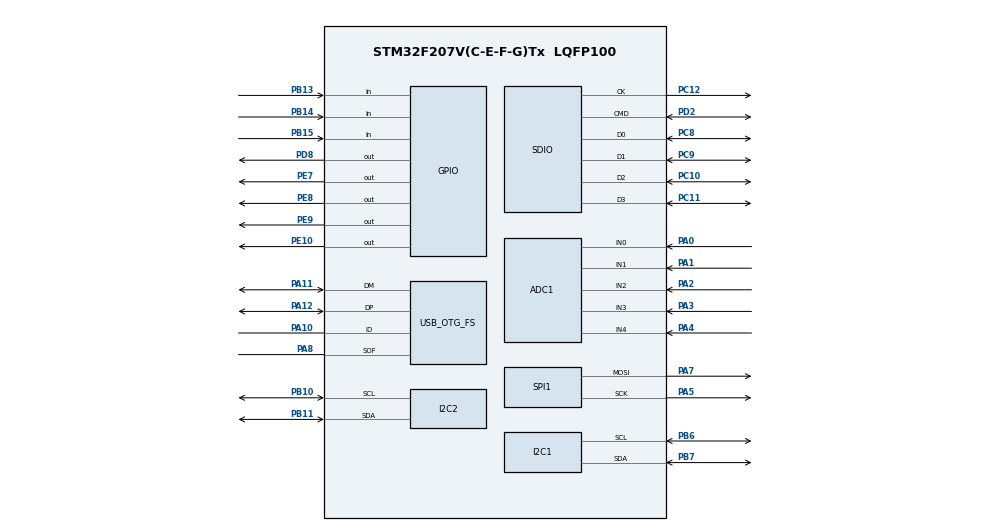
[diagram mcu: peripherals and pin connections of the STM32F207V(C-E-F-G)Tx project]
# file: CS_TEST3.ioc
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ADC1.Channel-0\#ChannelRegularConversion=ADC_CHANNEL_TEMPSENSOR
ADC1.NbrOfConversionFlag=1
ADC1.Rank-0\#ChannelRegularConversion=1
ADC1.SamplingTime-0\#ChannelRegularConversion=ADC_SAMPLETIME_3CYCLES
ADC1.master=1
Dma.I2C1_RX.1.Channel=DMA_CHANNEL_1
Dma.I2C1_RX.1.Direction=DMA_PERIPH_TO_MEMORY
Dma.I2C1_RX.1.FIFOMode=DMA_FIFOMODE_ENABLE
Dma.I2C1_RX.1.FIFOThreshold=DMA_FIFO_THRESHOLD_HALFFULL
Dma.I2C1_RX.1.Instance=DMA1_Stream0
Dma.I2C1_RX.1.MemBurst=DMA_MBURST_SINGLE
Dma.I2C1_RX.1.MemDataAlignment=DMA_MDATAALIGN_BYTE
Dma.I2C1_RX.1.MemInc=DMA_MINC_ENABLE
Dma.I2C1_RX.1.Mode=DMA_CIRCULAR
Dma.I2C1_RX.1.PeriphBurst=DMA_PBURST_SINGLE
Dma.I2C1_RX.1.PeriphDataAlignment=DMA_PDATAALIGN_BYTE
Dma.I2C1_RX.1.PeriphInc=DMA_PINC_DISABLE
Dma.I2C1_RX.1.Priority=DMA_PRIORITY_LOW
Dma.Request0=SDIO
Dma.Request1=I2C1_RX
Dma.SDIO.0.Channel=DMA_CHANNEL_4
Dma.SDIO.0.Direction=DMA_MEMORY_TO_PERIPH
Dma.SDIO.0.FIFOMode=DMA_FIFOMODE_ENABLE
Dma.SDIO.0.FIFOThreshold=DMA_FIFO_THRESHOLD_HALFFULL
Dma.SDIO.0.Instance=DMA2_Stream3
Dma.SDIO.0.MemBurst=DMA_MBURST_SINGLE
Dma.SDIO.0.MemDataAlignment=DMA_MDATAALIGN_BYTE
Dma.SDIO.0.MemInc=DMA_MINC_DISABLE
Dma.SDIO.0.Mode=DMA_PFCTRL
Dma.SDIO.0.PeriphBurst=DMA_PBURST_SINGLE
Dma.SDIO.0.PeriphDataAlignment=DMA_PDATAALIGN_BYTE
Dma.SDIO.0.PeriphInc=DMA_PINC_DISABLE
Dma.SDIO.0.Priority=DMA_PRIORITY_LOW
I2C1.GeneralCallMode=I2C_GENERALCALL_ENABLED
Mcu.Family=STM32F2
Mcu.Name=STM32F207V(C-E-F-G)Tx
Mcu.Package=LQFP100
NVIC.PriorityGroup=NVIC_PRIORITYGROUP_0
PA0-WKUP.Signal=ADCx_IN0
PA1.Signal=ADCx_IN1
PA10.Mode=OTG/Dual_Role_Device
PA10.Signal=USB_OTG_FS_ID
PA11.Mode=OTG/Dual_Role_Device
PA11.Signal=USB_OTG_FS_DM
PA12.Mode=OTG/Dual_Role_Device
PA12.Signal=USB_OTG_FS_DP
PA13.Mode=JTAG(4-pin)
PA13.Signal=SYS_JTMS-SWDIO
PA14.Mode=JTAG(4-pin)
PA14.Signal=SYS_JTCK-SWCLK
PA15.Mode=JTAG(4-pin)
PA15.Signal=SYS_JTDI
PA2.Signal=ADCx_IN2
PA3.Signal=ADCx_IN3
PA4.Signal=ADCx_IN4
PA5.Mode=TX_Only_Simplex_Unidirect_Master
PA5.Signal=SPI1_SCK
PA7.Mode=TX_Only_Simplex_Unidirect_Master
PA7.Signal=SPI1_MOSI
PA8.Mode=Activate_SOF_FS
PA8.Signal=USB_OTG_FS_SOF
PB10.Mode=I2C
PB10.Signal=I2C2_SCL
PB11.Mode=I2C
PB11.Signal=I2C2_SDA
PB13.GPIO_Mode=GPIO_MODE_INPUT
PB13.GPIO_PuPd=GPIO_PULLUP
PB13.Signal=GPIO_Input
PB14.GPIO_Mode=GPIO_MODE_INPUT
PB14.GPIO_PuPd=GPIO_PULLUP
PB14.Signal=GPIO_Input
PB15.GPIO_Mode=GPIO_MODE_INPUT
PB15.GPIO_PuPd=GPIO_PULLUP
PB15.Signal=GPIO_Input
PB3.Mode=JTAG(4-pin)
PB3.Signal=SYS_JTDO-SWO
PB6.Mode=I2C
PB6.Signal=I2C1_SCL
PB7.Mode=I2C
PB7.Signal=I2C1_SDA
PC10.Mode=SD_4_bits_Wide_bus
PC10.Signal=SDIO_D2
PC11.Mode=SD_4_bits_Wide_bus
PC11.Signal=SDIO_D3
PC12.Mode=SD_4_bits_Wide_bus
PC12.Signal=SDIO_CK
PC14-OSC32_IN.Mode=LSE-External-Oscillator
PC14-OSC32_IN.Signal=RCC_OSC32_IN
PC15-OSC32_OUT.Mode=LSE-External-Oscillator
PC15-OSC32_OUT.Signal=RCC_OSC32_OUT
PC8.Mode=SD_4_bits_Wide_bus
PC8.Signal=SDIO_D0
PC9.Mode=SD_4_bits_Wide_bus
PC9.Signal=SDIO_D1
PD2.Mode=SD_4_bits_Wide_bus
PD2.Signal=SDIO_CMD
PD8.GPIO_ModeDefaultOutputPP=GPIO_MODE_OUTPUT_PP
PD8.GPIO_PuPd=GPIO_NOPULL
PD8.GPIO_Speed=GPIO_SPEED_LOW
PD8.Signal=GPIO_Output
PE10.GPIO_ModeDefaultOutputPP=GPIO_MODE_OUTPUT_OD
PE10.GPIO_PuPd=GPIO_NOPULL
PE10.GPIO_Speed=GPIO_SPEED_LOW
PE10.Signal=GPIO_Output
PE7.GPIO_ModeDefaultOutputPP=GPIO_MODE_OUTPUT_OD
PE7.GPIO_PuPd=GPIO_NOPULL
PE7.GPIO_Speed=GPIO_SPEED_LOW
PE7.Signal=GPIO_Output
PE8.GPIO_ModeDefaultOutputPP=GPIO_MODE_OUTPUT_OD
PE8.GPIO_PuPd=GPIO_PULLUP
PE8.GPIO_Speed=GPIO_SPEED_LOW
PE8.Signal=GPIO_Output
PE9.GPIO_ModeDefaultOutputPP=GPIO_MODE_OUTPUT_OD
PE9.GPIO_PuPd=GPIO_PULLUP
PE9.GPIO_Speed=GPIO_SPEED_LOW
PE9.Signal=GPIO_Output
PH0-OSC_IN.Mode=HSE-External-Clock-Source
PH0-OSC_IN.Signal=RCC_OSC_IN
PH1-OSC_OUT.Mode=HSE-External-Clock-Source
PH1-OSC_OUT.Signal=RCC_OSC_OUT
ProjectManager.TargetToolchain=EWARM 6.70
RCC.EnbaleCSS=true
RCC.HSE_VALUE=25000000
RCC.HSI_VALUE=16000000
RCC.LSE_VALUE=32768
RCC.SYSCLKSource=RCC_SYSCLKSOURCE_HSE
SH.ADCx_IN0.0=ADC1_IN0,IN0
SH.ADCx_IN1.0=ADC1_IN1,IN1
SH.ADCx_IN2.0=ADC1_IN2,IN2
SH.ADCx_IN3.0=ADC1_IN3,IN3
SH.ADCx_IN4.0=ADC1_IN4,IN4
SPI1.BaudRatePrescaler-TX_Only_Simplex_Unidirect_Master=SPI_BAUDRATEPRESCALER_2
SPI1.CalculateBaudRate-TX_Only_Simplex_Unidirect_Master=12.5 MBits/s
SPI1.Mode-TX_Only_Simplex_Unidirect_Master=SPI_MODE_MASTER
VP_ADC1_TempSens_Input.Mode=IN-TempSens
VP_FATFS_VS_SDIO.Mode=SDIO
VP_TIM4_VS_ClockSourceINT.Mode=Internal
VP_TIM4_VS_OPM.Mode=OPM_bit
VP_WWDG_VS_WWDG.Mode=WWDG_Activate

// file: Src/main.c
/**
  ******************************************************************************
  * File Name          : main.c
  * Date               : 24/02/2015 00:59:37
  * Description        : Main program body
  ******************************************************************************
  *
  * COPYRIGHT(c) 2015 STMicroelectronics
  *
  * Redistribution and use in source and binary forms, with or without modification,
  * are permitted provided that the following conditions are met:
  *   1. Redistributions of source code must retain the above copyright notice,
  *      this list of conditions and the following disclaimer.
  *   2. Redistributions in binary form must reproduce the above copyright notice,
  *      this list of conditions and the following disclaimer in the documentation
  *      and/or other materials provided with the distribution.
  *   3. Neither the name of STMicroelectronics nor the names of its contributors
  *      may be used to endorse or promote products derived from this software
  *      without specific prior written permission.
  *
  * THIS SOFTWARE IS PROVIDED BY THE COPYRIGHT HOLDERS AND CONTRIBUTORS "AS IS"
  * AND ANY EXPRESS OR IMPLIED WARRANTIES, INCLUDING, BUT NOT LIMITED TO, THE
  * IMPLIED WARRANTIES OF MERCHANTABILITY AND FITNESS FOR A PARTICULAR PURPOSE ARE
  * DISCLAIMED. IN NO EVENT SHALL THE COPYRIGHT HOLDER OR CONTRIBUTORS BE LIABLE
  * FOR ANY DIRECT, INDIRECT, INCIDENTAL, SPECIAL, EXEMPLARY, OR CONSEQUENTIAL
  * DAMAGES (INCLUDING, BUT NOT LIMITED TO, PROCUREMENT OF SUBSTITUTE GOODS OR
  * SERVICES; LOSS OF USE, DATA, OR PROFITS; OR BUSINESS INTERRUPTION) HOWEVER
  * CAUSED AND ON ANY THEORY OF LIABILITY, WHETHER IN CONTRACT, STRICT LIABILITY,
  * OR TORT (INCLUDING NEGLIGENCE OR OTHERWISE) ARISING IN ANY WAY OUT OF THE USE
  * OF THIS SOFTWARE, EVEN IF ADVISED OF THE POSSIBILITY OF SUCH DAMAGE.
  *
  ******************************************************************************
  */

#include "stm32f2xx_hal.h"
#include "ff.h"
#include "ff_gen_drv.h"
#include "sd_diskio.h" /* defines SD_Driver as external */
#include "adc.h"
#include "dma.h"
#include "i2c.h"
#include "sdio.h"
#include "spi.h"
#include "tim.h"
#include "usb_otg.h"
#include "wwdg.h"
#include "gpio.h"

uint8_t SD_DriverNum;      /* FatFS SD part */
char SD_Path[4];           /* SD logical drive path */

void SystemClock_Config(void);

int main(void)
{

  /* MCU Configuration----------------------------------------------------------*/

  /* Reset of all peripherals, Initializes the Flash interface and the Systick. */
  HAL_Init();

  /* Configure the system clock */
  SystemClock_Config();

  /* System interrupt init*/
  /* Sets the priority grouping field */
  HAL_NVIC_SetPriorityGrouping(NVIC_PRIORITYGROUP_0);
  HAL_NVIC_SetPriority(SysTick_IRQn, 0, 0);

  /* Initialize all configured peripherals */
  MX_GPIO_Init();
  MX_DMA_Init();
  MX_ADC1_Init();
  MX_I2C1_Init();
  MX_I2C2_Init();
  MX_SDIO_SD_Init();
  MX_SPI1_Init();
  MX_TIM4_Init();
  MX_USB_OTG_FS_USB_Init();
  MX_WWDG_Init();

  /* USER CODE BEGIN 2 */
/*
GPIO_InitTypeDef GPIO_InitStruct;

GPIO_InitStruct.Pin = GPIO_PIN_10;
GPIO_InitStruct.Mode = GPIO_MODE_OUTPUT_PP;
GPIO_InitStruct.Pull = GPIO_PULLUP;
GPIO_InitStruct.Speed = GPIO_SPEED_FAST;
HAL_GPIO_Init(GPIOE, &GPIO_InitStruct);
*/
  /* USER CODE END 2 */

  /*## FatFS: Link the SD disk I/O driver ###############################*/
  SD_DriverNum = FATFS_LinkDriver(&SD_Driver, SD_Path);

  /* USER CODE BEGIN 3 */
/*	__HAL_RCC_HSI_ENABLE();
	__HAL_RCC_LSI_ENABLE();
	__AHB1_FORCE_RESET();
	__AHB2_FORCE_RESET();

	__GPIOE_FORCE_RESET();
	__GPIOE_CLK_SLEEP_ENABLE();
	__GPIOE_CLK_ENABLE();
*/
/* Infinite loop */
  while (1)
  {
	HAL_GPIO_WritePin(GPIOD, GPIO_PIN_8, GPIO_PIN_SET);
	HAL_GPIO_WritePin(GPIOE, GPIO_PIN_9, GPIO_PIN_SET);
	HAL_GPIO_WritePin(GPIOE, GPIO_PIN_8, GPIO_PIN_SET);
	HAL_GPIO_WritePin(GPIOE, GPIO_PIN_7, GPIO_PIN_SET);
	//GPIOE_BSSR = 0x0300;
  	//for(index; index<40000; index++){
	//	__asm__("nop");
	//}
	//HAL_GPIO_WritePin(GPIOE, GPIO_PIN_7, GPIO_PIN_RESET);
  }
  /* USER CODE END 3 */

}

/** System Clock Configuration
*/
void SystemClock_Config(void)
{

  RCC_ClkInitTypeDef RCC_ClkInitStruct;
  RCC_OscInitTypeDef RCC_OscInitStruct;

  RCC_OscInitStruct.OscillatorType = RCC_OSCILLATORTYPE_HSI|RCC_OSCILLATORTYPE_HSE;
  RCC_OscInitStruct.HSEState = RCC_HSE_BYPASS;
  RCC_OscInitStruct.HSIState = RCC_HSI_ON;
  RCC_OscInitStruct.HSICalibrationValue = 6;
  RCC_OscInitStruct.PLL.PLLState = RCC_PLL_ON;
  RCC_OscInitStruct.PLL.PLLSource = RCC_PLLSOURCE_HSI;
  RCC_OscInitStruct.PLL.PLLM = 16;
  RCC_OscInitStruct.PLL.PLLN = 192;
  RCC_OscInitStruct.PLL.PLLP = RCC_PLLP_DIV2;
  RCC_OscInitStruct.PLL.PLLQ = 4;
  HAL_RCC_OscConfig(&RCC_OscInitStruct);

  RCC_ClkInitStruct.ClockType = RCC_CLOCKTYPE_SYSCLK;
  RCC_ClkInitStruct.SYSCLKSource = RCC_SYSCLKSOURCE_HSE;
  RCC_ClkInitStruct.AHBCLKDivider = RCC_SYSCLK_DIV1;
  RCC_ClkInitStruct.APB1CLKDivider = RCC_HCLK_DIV1;
  RCC_ClkInitStruct.APB2CLKDivider = RCC_HCLK_DIV1;
  HAL_RCC_ClockConfig(&RCC_ClkInitStruct, FLASH_LATENCY_0);

  HAL_RCC_EnableCSS();

}

/************************ (C) COPYRIGHT STMicroelectronics *****END OF FILE****/
